# ATSAMA5D27WLSOM1 device description
Architecture: CORTEX-A5; Family: SAMA5; Series: SAMA5D2
Registers are 32-bit, read-write, no defined reset value unless marked. A register's access mark holds for its fields unless they carry their own. Offsets are from the block's base; [hi:lo] are bit positions; {n}, {i} and the like mark numbered series.

## SFRBU — Special Function Registers Backup
Instances: SFRBU 0xFC05C000
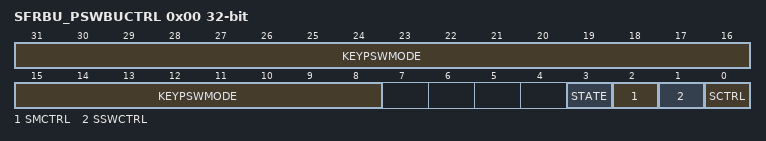
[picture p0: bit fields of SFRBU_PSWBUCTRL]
0x00 SFRBU_PSWBUCTRL — Power Switch BU Control Register
  [31:8] KEYPSWMODE
  [3] STATE — Power Switch BU state (Read-only)
  [2] SMCTRL — Allow Power Switch BU Control by Security Module Autobackup (Hardware)
  [1] SSWCTRL — Power Switch BU Source Selection
  [0] SCTRL — Power Switch BU Software Control
0x04 SFRBU_TSRANGECFG — TS Range Configuration Register
  [0] TSHRSEL — Temperature Sensor Range Selection
0x10 SFRBU_DDRBUMCR — DDR BU Mode Control Register
  [0] BUMEN — DDR BU Mode Enable
0x14 SFRBU_RXLPPUCR — RXLP Pull-Up Control Register
  [0] RXDPUCTRL — RXLP RXD Pull-Up Control

## SHA — Secure Hash Algorithm
Instances: SHA 0xF0028000
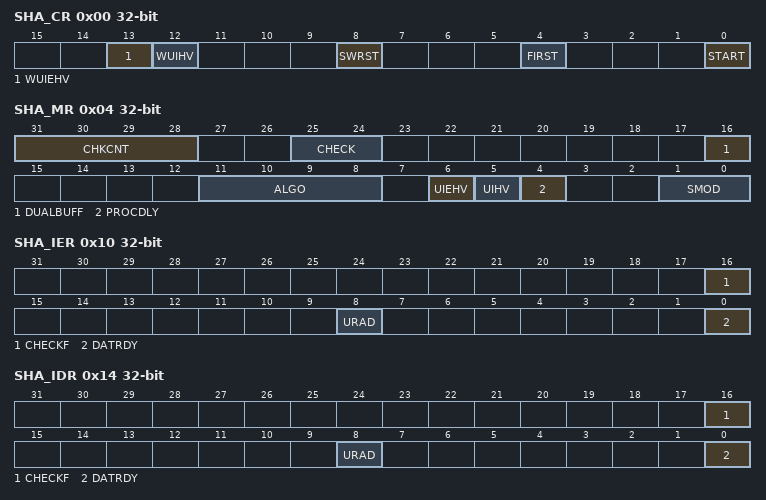
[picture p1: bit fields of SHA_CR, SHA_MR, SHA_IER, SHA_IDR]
0x00 SHA_CR wo — Control Register
  [13] WUIEHV — Write User Initial or Expected Hash Values
  [12] WUIHV — Write User Initial Hash Values
  [8] SWRST — Software Reset
  [4] FIRST — First Block of a Message
  [0] START — Start Processing
0x04 SHA_MR — Mode Register
  [31:28] CHKCNT — Check Counter
  [25:24] CHECK — Hash Check
    0=NO_CHECK (No check is performed); 1=CHECK_EHV (Check is performed with expected hash stored in internal expected hash value registers.); 2=CHECK_MESSAGE (Check is performed with expected hash provided after the message.)
  [16] DUALBUFF — Dual Input Buffer
    0=INACTIVE (SHA_IDATARx and SHA_IODATARx cannot be written during processing of previous block.); 1=ACTIVE (SHA_IDATARx and SHA_IODATARx can be written during processing of previous block when SMOD value = 2. It speeds up the overall runtime of large files.)
  [11:8] ALGO — SHA Algorithm
    0=SHA1 (SHA1 algorithm processed); 1=SHA256 (SHA256 algorithm processed); 2=SHA384 (SHA384 algorithm processed); 3=SHA512 (SHA512 algorithm processed); 4=SHA224 (SHA224 algorithm processed); 8=HMAC_SHA1 (HMAC algorithm with SHA1 Hash processed); 9=HMAC_SHA256 (HMAC algorithm with SHA256 Hash processed); 10=HMAC_SHA384 (HMAC algorithm with SHA384 Hash processed); 11=HMAC_SHA512 (HMAC algorithm with SHA512 Hash processed); 12=HMAC_SHA224 (HMAC algorithm with SHA224 Hash processed)
  [6] UIEHV — User Initial or Expected Hash Value Registers
  [5] UIHV — User Initial Hash Value Registers
  [4] PROCDLY — Processing Delay
    0=SHORTEST (SHA processing runtime is the shortest one); 1=LONGEST (SHA processing runtime is the longest one (reduces the SHA bandwidth requirement, reduces the system bus overload))
  [1:0] SMOD — Start Mode
    0=MANUAL_START (Manual mode); 1=AUTO_START (Auto mode); 2=IDATAR0_START (SHA_IDATAR0 access only mode (mandatory when DMA is used))
0x10 SHA_IER wo — Interrupt Enable Register
  [16] CHECKF — Check Done Interrupt Enable
  [8] URAD — Unspecified Register Access Detection Interrupt Enable
  [0] DATRDY — Data Ready Interrupt Enable
0x14 SHA_IDR wo — Interrupt Disable Register
  [16] CHECKF — Check Done Interrupt Disable
  [8] URAD — Unspecified Register Access Detection Interrupt Disable
  [0] DATRDY — Data Ready Interrupt Disable
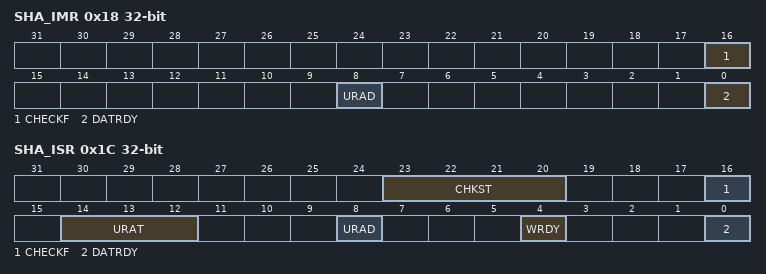
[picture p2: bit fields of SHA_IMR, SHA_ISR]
0x18 SHA_IMR ro — Interrupt Mask Register
  [16] CHECKF — Check Done Interrupt Mask
  [8] URAD — Unspecified Register Access Detection Interrupt Mask
  [0] DATRDY — Data Ready Interrupt Mask
0x1C SHA_ISR ro — Interrupt Status Register
  [23:20] CHKST — Check Status (cleared by writing START or SWRST bits in SHA_CR or by reading SHA_IODATARx)
  [16] CHECKF — Check Done Status (cleared by writing START or SWRST bits in SHA_CR or by reading SHA_IODATARx)
  [14:12] URAT — Unspecified Register Access Type (cleared by writing a 1 to SWRST bit in SHA_CR)
  [8] URAD — Unspecified Register Access Detection Status (cleared by writing a 1 to SWRST bit in SHA_CR)
  [4] WRDY — Input Data Register Write Ready
  [0] DATRDY — Data Ready (cleared by writing a 1 to bit SWRST or START in SHA_CR, or by reading SHA_IODATARx)
0x20 SHA_MSR — Message Size Register
  [31:0] MSGSIZE — Message Size
0x30 SHA_BCR — Bytes Count Register
  [31:0] BYTCNT — Remaining Byte Count Before Auto Padding
{0x40+4i} SHA_IDATAR[{i}] (i=0..15) wo — Input Data 0 Register
  [31:0] IDATA — Input Data
{0x80+4i} SHA_IODATAR[{i}] (i=0..15) — Input/Output Data 0 Register
  [31:0] IODATA — Input/Output Data
